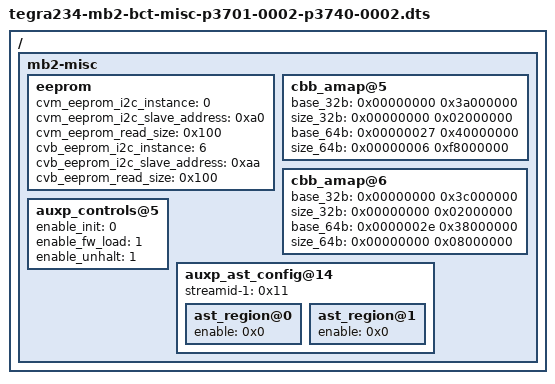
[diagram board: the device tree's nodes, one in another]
/*
 * SPDX-FileCopyrightText: Copyright (c) 2022-2023, NVIDIA CORPORATION & AFFILIATES. All rights reserved.
 * SPDX-License-Identifier: BSD-3-Clause
 *
 * Redistribution and use in source and binary forms, with or without
 * modification, are permitted provided that the following conditions are met:
 *
 * 1. Redistributions of source code must retain the above copyright notice, this
 * list of conditions and the following disclaimer.
 *
 * 2. Redistributions in binary form must reproduce the above copyright notice,
 * this list of conditions and the following disclaimer in the documentation
 * and/or other materials provided with the distribution.
 *
 * 3. Neither the name of the copyright holder nor the names of its
 * contributors may be used to endorse or promote products derived from
 * this software without specific prior written permission.
 *
 * THIS SOFTWARE IS PROVIDED BY THE COPYRIGHT HOLDERS AND CONTRIBUTORS "AS IS"
 * AND ANY EXPRESS OR IMPLIED WARRANTIES, INCLUDING, BUT NOT LIMITED TO, THE
 * IMPLIED WARRANTIES OF MERCHANTABILITY AND FITNESS FOR A PARTICULAR PURPOSE ARE
 * DISCLAIMED. IN NO EVENT SHALL THE COPYRIGHT HOLDER OR CONTRIBUTORS BE LIABLE
 * FOR ANY DIRECT, INDIRECT, INCIDENTAL, SPECIAL, EXEMPLARY, OR CONSEQUENTIAL
 * DAMAGES (INCLUDING, BUT NOT LIMITED TO, PROCUREMENT OF SUBSTITUTE GOODS OR
 * SERVICES; LOSS OF USE, DATA, OR PROFITS; OR BUSINESS INTERRUPTION) HOWEVER
 * CAUSED AND ON ANY THEORY OF LIABILITY, WHETHER IN CONTRACT, STRICT LIABILITY,
 * OR TORT (INCLUDING NEGLIGENCE OR OTHERWISE) ARISING IN ANY WAY OUT OF THE USE
 * OF THIS SOFTWARE, EVEN IF ADVISED OF THE POSSIBILITY OF SUCH DAMAGE.
 */
/dts-v1/;

#include "tegra234-mb2-bct-common.dtsi"
/ {
    mb2-misc {
        eeprom {
            cvm_eeprom_i2c_instance = <0>; //Starts from I2C bus 0
            cvm_eeprom_i2c_slave_address = <0xa0>; //0x50 << 1
            cvm_eeprom_read_size = <0x100>;
            cvb_eeprom_i2c_instance = <6>; //Starts from I2C bus 0
            cvb_eeprom_i2c_slave_address = <0xaa>; //0x55 << 1
            cvb_eeprom_read_size = <0x100>;
        };
        cbb_amap@5 {
                base_32b = <0x00000000 0x3a000000>;
                size_32b = <0x00000000 0x02000000>;
                base_64b = <0x00000027 0x40000000>;
                size_64b = <0x00000006 0xf8000000>;
        };
        cbb_amap@6 {
                base_32b = <0x00000000 0x3c000000>;
                size_32b = <0x00000000 0x02000000>;
                base_64b = <0x0000002e 0x38000000>;
                size_64b = <0x00000000 0x08000000>;
        };

        /* Control fields for FSI cluster. */
        auxp_controls@5 {
		enable_init = <0>;
		enable_fw_load = <1>;
		enable_unhalt = <1>;
        };

	/* Override Configuration fields for FSI CHSM AST. */
	auxp_ast_config@14 {
		streamid-1 = <0x11>;
		ast_region@0 {
			enable = <0x0>;
		};
		ast_region@1 {
			enable = <0x0>;
		};
	};
    };
};
